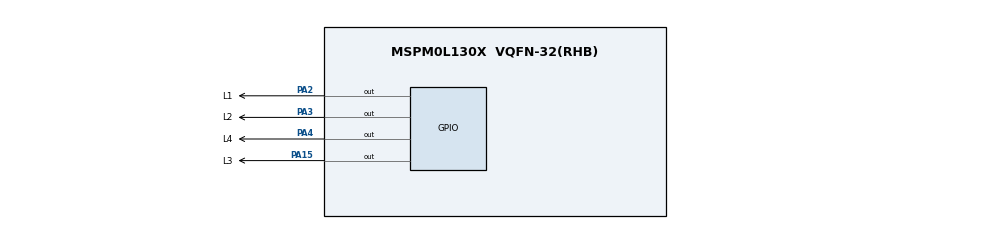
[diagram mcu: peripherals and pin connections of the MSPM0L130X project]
/**
 * @cliArgs --device "MSPM0L130X" --package "VQFN-32(RHB)" --part "Default" --product "mspm0_sdk@1.20.01.06"
 * @versions {"tool":"1.18.1+3343"}
 */

/**
 * Import the modules used in this configuration.
 */
const Board  = scripting.addModule("/ti/driverlib/Board");
const GPIO   = scripting.addModule("/ti/driverlib/GPIO", {}, false);
const GPIO1  = GPIO.addInstance();
const GPIO2  = GPIO.addInstance();
const SYSCTL = scripting.addModule("/ti/driverlib/SYSCTL");

/**
 * Write custom configuration values to the imported modules.
 */
const gate6  = system.clockTree["MFCLKGATE"];
gate6.enable = true;

const gate7  = system.clockTree["MFPCLKGATE"];
gate7.enable = true;


GPIO1.$name                              = "Switch";
GPIO1.associatedPins.create(8);
GPIO1.associatedPins[0].$name            = "H1";
GPIO1.associatedPins[0].assignedPin      = "0";
GPIO1.associatedPins[1].direction        = "INPUT";
GPIO1.associatedPins[1].$name            = "V1";
GPIO1.associatedPins[1].internalResistor = "PULL_UP";
GPIO1.associatedPins[1].assignedPin      = "13";
GPIO1.associatedPins[2].$name            = "H2";
GPIO1.associatedPins[2].assignedPin      = "1";
GPIO1.associatedPins[3].direction        = "INPUT";
GPIO1.associatedPins[3].$name            = "V2";
GPIO1.associatedPins[3].internalResistor = "PULL_UP";
GPIO1.associatedPins[3].assignedPin      = "14";
GPIO1.associatedPins[4].$name            = "H3";
GPIO1.associatedPins[4].assignedPort     = "PORTA";
GPIO1.associatedPins[4].assignedPin      = "7";
GPIO1.associatedPins[5].$name            = "V3";
GPIO1.associatedPins[5].direction        = "INPUT";
GPIO1.associatedPins[5].assignedPort     = "PORTA";
GPIO1.associatedPins[5].internalResistor = "PULL_UP";
GPIO1.associatedPins[5].assignedPin      = "17";
GPIO1.associatedPins[6].$name            = "H4";
GPIO1.associatedPins[6].assignedPort     = "PORTA";
GPIO1.associatedPins[6].assignedPin      = "12";
GPIO1.associatedPins[7].$name            = "V4";
GPIO1.associatedPins[7].assignedPort     = "PORTA";
GPIO1.associatedPins[7].internalResistor = "PULL_UP";
GPIO1.associatedPins[7].direction        = "INPUT";
GPIO1.associatedPins[7].assignedPin      = "18";

GPIO2.$name                          = "L";
GPIO2.associatedPins.create(4);
GPIO2.associatedPins[0].$name        = "L1";
GPIO2.associatedPins[0].assignedPort = "PORTA";
GPIO2.associatedPins[0].pin.$assign  = "PA2";
GPIO2.associatedPins[1].$name        = "L2";
GPIO2.associatedPins[1].assignedPort = "PORTA";
GPIO2.associatedPins[1].pin.$assign  = "PA3";
GPIO2.associatedPins[2].$name        = "L3";
GPIO2.associatedPins[2].assignedPort = "PORTA";
GPIO2.associatedPins[2].pin.$assign  = "PA15";
GPIO2.associatedPins[3].$name        = "L4";
GPIO2.associatedPins[3].assignedPort = "PORTA";
GPIO2.associatedPins[3].pin.$assign  = "PA4";

SYSCTL.MFPCLKEn    = true;
SYSCTL.MDIV        = "2";
SYSCTL.clockTreeEn = true;

/**
 * Pinmux solution for unlocked pins/peripherals. This ensures that minor changes to the automatic solver in a future
 * version of the tool will not impact the pinmux you originally saw.  These lines can be completely deleted in order to
 * re-solve from scratch.
 */
Board.peripheral.$suggestSolution            = "DEBUGSS";
Board.peripheral.swclkPin.$suggestSolution   = "PA20";
Board.peripheral.swdioPin.$suggestSolution   = "PA19";
GPIO1.associatedPins[0].pin.$suggestSolution = "PA0";
GPIO1.associatedPins[1].pin.$suggestSolution = "PA13";
GPIO1.associatedPins[2].pin.$suggestSolution = "PA1";
GPIO1.associatedPins[3].pin.$suggestSolution = "PA14";
GPIO1.associatedPins[4].pin.$suggestSolution = "PA7";
GPIO1.associatedPins[5].pin.$suggestSolution = "PA17/OPA1.IN0-";
GPIO1.associatedPins[6].pin.$suggestSolution = "PA12";
GPIO1.associatedPins[7].pin.$suggestSolution = "PA18";
